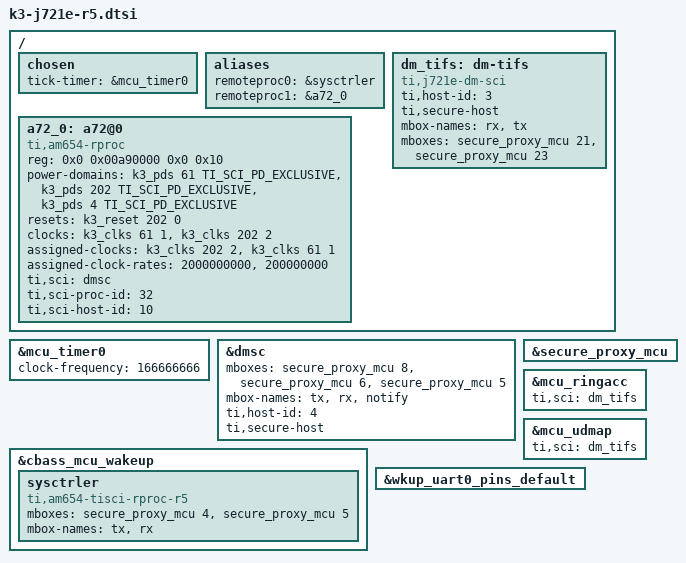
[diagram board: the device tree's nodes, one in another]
// SPDX-License-Identifier: GPL-2.0
/*
 * Copyright (C) 2024 Texas Instruments Incorporated - https://www.ti.com/
 */

/ {
	chosen {
		tick-timer = &mcu_timer0;
	};

	aliases {
		remoteproc0 = &sysctrler;
		remoteproc1 = &a72_0;
	};

	a72_0: a72@0 {
		compatible = "ti,am654-rproc";
		reg = <0x0 0x00a90000 0x0 0x10>;
		power-domains = <&k3_pds 61 TI_SCI_PD_EXCLUSIVE>,
				<&k3_pds 202 TI_SCI_PD_EXCLUSIVE>,
				<&k3_pds 4 TI_SCI_PD_EXCLUSIVE>;
		resets = <&k3_reset 202 0>;
		clocks = <&k3_clks 61 1>, <&k3_clks 202 2>;
		clock-names = "gtc", "core";
		assigned-clocks = <&k3_clks 202 2>, <&k3_clks 61 1>;
		assigned-clock-rates = <2000000000>, <200000000>;
		ti,sci = <&dmsc>;
		ti,sci-proc-id = <32>;
		ti,sci-host-id = <10>;
		bootph-pre-ram;
	};

	dm_tifs: dm-tifs {
		compatible = "ti,j721e-dm-sci";
		ti,host-id = <3>;
		ti,secure-host;
		mbox-names = "rx", "tx";
		mboxes= <&secure_proxy_mcu 21>,
			<&secure_proxy_mcu 23>;
		bootph-pre-ram;
	};
};

&mcu_timer0 {
	/delete-property/ clocks;
	/delete-property/ clocks-names;
	/delete-property/ assigned-clocks;
	/delete-property/ assigned-clock-parents;
	clock-frequency = <166666666>;
	bootph-pre-ram;
};

&dmsc {
	mboxes= <&secure_proxy_mcu 8>, <&secure_proxy_mcu 6>, <&secure_proxy_mcu 5>;
	mbox-names = "tx", "rx", "notify";
	ti,host-id = <4>;
	ti,secure-host;
};

&secure_proxy_mcu {
	bootph-pre-ram;
	/* We require this for boot handshake */
	status = "okay";
};

&cbass_mcu_wakeup {
	sysctrler: sysctrler {
		bootph-pre-ram;
		compatible = "ti,am654-tisci-rproc-r5";
		mboxes= <&secure_proxy_mcu 4>, <&secure_proxy_mcu 5>;
		mbox-names = "tx", "rx";
	};
};

&mcu_ringacc {
	ti,sci = <&dm_tifs>;
};

&mcu_udmap {
	ti,sci = <&dm_tifs>;
};

&wkup_uart0_pins_default {
	bootph-pre-ram;
};
